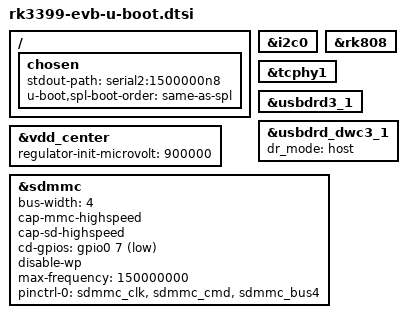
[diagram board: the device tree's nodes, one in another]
// SPDX-License-Identifier: GPL-2.0+
/*
 * Copyright (C) 2019 Jagan Teki <jagan@amarulasolutions.com>
 */

#include "rk3399-u-boot.dtsi"
#include "rk3399-sdram-lpddr3-4GB-1600.dtsi"

/ {
	chosen {
		stdout-path = "serial2:1500000n8";
		u-boot,spl-boot-order = "same-as-spl", &sdhci, &sdmmc;
	};
};

&i2c0 {
	bootph-all;
};

&rk808 {
	bootph-all;
};

&tcphy1 {
	status = "okay";
};

&usbdrd3_1 {
	status = "okay";
};

&usbdrd_dwc3_1 {
	dr_mode = "host";
	status = "okay";
};

&vdd_center {
	regulator-init-microvolt = <900000>;
};

&sdmmc {
	bootph-all;
	bus-width = <4>;
	cap-mmc-highspeed;
	cap-sd-highspeed;
	cd-gpios = <&gpio0 7 GPIO_ACTIVE_LOW>;
	disable-wp;
	max-frequency = <150000000>;
	pinctrl-names = "default";
	pinctrl-0 = <&sdmmc_clk &sdmmc_cmd &sdmmc_bus4>;
	status = "okay";
};
